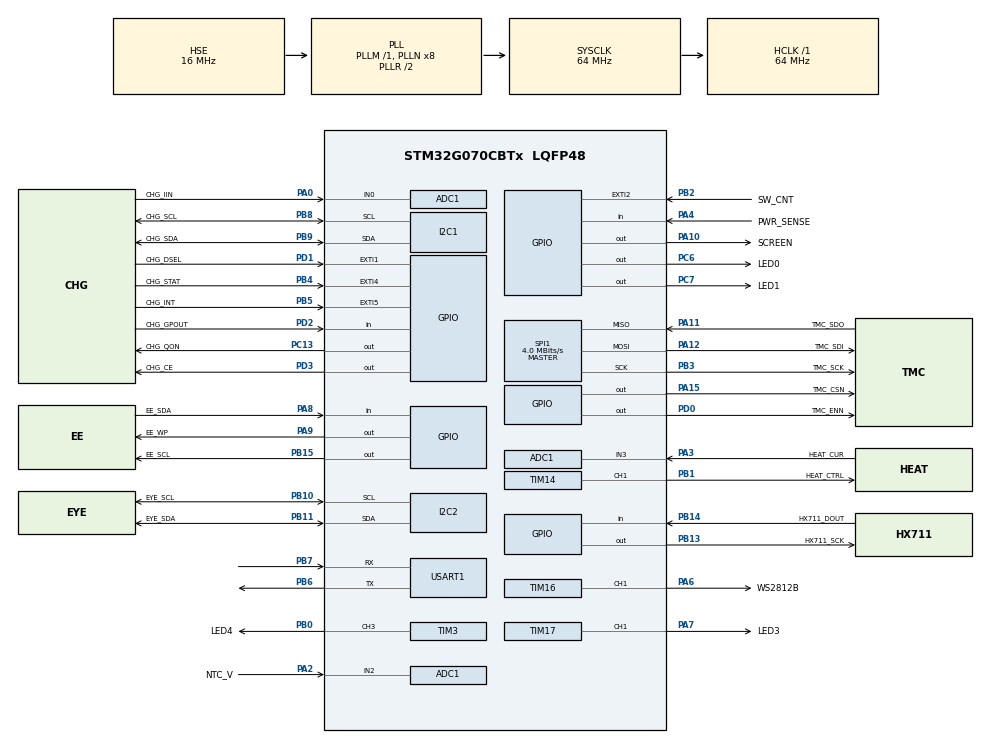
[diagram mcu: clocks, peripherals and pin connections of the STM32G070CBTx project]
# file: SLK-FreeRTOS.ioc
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ADC1.Channel-0\#ChannelRegularConversion=ADC_CHANNEL_0
ADC1.Channel-1\#ChannelRegularConversion=ADC_CHANNEL_2
ADC1.Channel-2\#ChannelRegularConversion=ADC_CHANNEL_3
ADC1.ClockPrescaler=ADC_CLOCK_ASYNC_DIV32
ADC1.ContinuousConvMode=ENABLE
ADC1.DMAContinuousRequests=ENABLE
ADC1.EOCSelection=ADC_EOC_SEQ_CONV
ADC1.NbrOfConversion=3
ADC1.NbrOfConversionFlag=1
ADC1.Overrun=ADC_OVR_DATA_OVERWRITTEN
ADC1.OversamplingMode=ENABLE
ADC1.Rank-0\#ChannelRegularConversion=1
ADC1.Rank-1\#ChannelRegularConversion=2
ADC1.Rank-2\#ChannelRegularConversion=3
ADC1.Ratio=ADC_OVERSAMPLING_RATIO_256
ADC1.Resolution=ADC_RESOLUTION_12B
ADC1.RightBitShift=ADC_RIGHTBITSHIFT_4
ADC1.SamplingTime-0\#ChannelRegularConversion=ADC_SAMPLINGTIME_COMMON_1
ADC1.SamplingTime-1\#ChannelRegularConversion=ADC_SAMPLINGTIME_COMMON_1
ADC1.SamplingTime-2\#ChannelRegularConversion=ADC_SAMPLINGTIME_COMMON_1
ADC1.SelectedChannel=ADC_CHANNEL_0|ADC_CHANNEL_2|ADC_CHANNEL_3
ADC1.master=1
Dma.ADC1.4.Direction=DMA_PERIPH_TO_MEMORY
Dma.ADC1.4.EventEnable=DISABLE
Dma.ADC1.4.Instance=DMA1_Channel5
Dma.ADC1.4.MemDataAlignment=DMA_MDATAALIGN_HALFWORD
Dma.ADC1.4.MemInc=DMA_MINC_ENABLE
Dma.ADC1.4.Mode=DMA_CIRCULAR
Dma.ADC1.4.PeriphDataAlignment=DMA_PDATAALIGN_HALFWORD
Dma.ADC1.4.PeriphInc=DMA_PINC_DISABLE
Dma.ADC1.4.Polarity=HAL_DMAMUX_REQ_GEN_RISING
Dma.ADC1.4.Priority=DMA_PRIORITY_LOW
Dma.ADC1.4.RequestNumber=1
Dma.ADC1.4.SignalID=NONE
Dma.ADC1.4.SyncEnable=DISABLE
Dma.ADC1.4.SyncPolarity=HAL_DMAMUX_SYNC_NO_EVENT
Dma.ADC1.4.SyncRequestNumber=1
Dma.ADC1.4.SyncSignalID=NONE
Dma.I2C1_RX.0.Direction=DMA_PERIPH_TO_MEMORY
Dma.I2C1_RX.0.EventEnable=DISABLE
Dma.I2C1_RX.0.Instance=DMA1_Channel1
Dma.I2C1_RX.0.MemDataAlignment=DMA_MDATAALIGN_BYTE
Dma.I2C1_RX.0.MemInc=DMA_MINC_ENABLE
Dma.I2C1_RX.0.Mode=DMA_NORMAL
Dma.I2C1_RX.0.PeriphDataAlignment=DMA_PDATAALIGN_BYTE
Dma.I2C1_RX.0.PeriphInc=DMA_PINC_DISABLE
Dma.I2C1_RX.0.Polarity=HAL_DMAMUX_REQ_GEN_RISING
Dma.I2C1_RX.0.Priority=DMA_PRIORITY_LOW
Dma.I2C1_RX.0.RequestNumber=1
Dma.I2C1_RX.0.SignalID=NONE
Dma.I2C1_RX.0.SyncEnable=DISABLE
Dma.I2C1_RX.0.SyncPolarity=HAL_DMAMUX_SYNC_NO_EVENT
Dma.I2C1_RX.0.SyncRequestNumber=1
Dma.I2C1_RX.0.SyncSignalID=NONE
Dma.I2C1_TX.1.Direction=DMA_MEMORY_TO_PERIPH
Dma.I2C1_TX.1.EventEnable=DISABLE
Dma.I2C1_TX.1.Instance=DMA1_Channel2
Dma.I2C1_TX.1.MemDataAlignment=DMA_MDATAALIGN_BYTE
Dma.I2C1_TX.1.MemInc=DMA_MINC_ENABLE
Dma.I2C1_TX.1.Mode=DMA_NORMAL
Dma.I2C1_TX.1.PeriphDataAlignment=DMA_PDATAALIGN_BYTE
Dma.I2C1_TX.1.PeriphInc=DMA_PINC_DISABLE
Dma.I2C1_TX.1.Polarity=HAL_DMAMUX_REQ_GEN_RISING
Dma.I2C1_TX.1.Priority=DMA_PRIORITY_LOW
Dma.I2C1_TX.1.RequestNumber=1
Dma.I2C1_TX.1.SignalID=NONE
Dma.I2C1_TX.1.SyncEnable=DISABLE
Dma.I2C1_TX.1.SyncPolarity=HAL_DMAMUX_SYNC_NO_EVENT
Dma.I2C1_TX.1.SyncRequestNumber=1
Dma.I2C1_TX.1.SyncSignalID=NONE
Dma.I2C2_RX.2.Direction=DMA_PERIPH_TO_MEMORY
Dma.I2C2_RX.2.EventEnable=DISABLE
Dma.I2C2_RX.2.Instance=DMA1_Channel3
Dma.I2C2_RX.2.MemDataAlignment=DMA_MDATAALIGN_BYTE
Dma.I2C2_RX.2.MemInc=DMA_MINC_ENABLE
Dma.I2C2_RX.2.Mode=DMA_NORMAL
Dma.I2C2_RX.2.PeriphDataAlignment=DMA_PDATAALIGN_BYTE
Dma.I2C2_RX.2.PeriphInc=DMA_PINC_DISABLE
Dma.I2C2_RX.2.Polarity=HAL_DMAMUX_REQ_GEN_RISING
Dma.I2C2_RX.2.Priority=DMA_PRIORITY_LOW
Dma.I2C2_RX.2.RequestNumber=1
Dma.I2C2_RX.2.SignalID=NONE
Dma.I2C2_RX.2.SyncEnable=DISABLE
Dma.I2C2_RX.2.SyncPolarity=HAL_DMAMUX_SYNC_NO_EVENT
Dma.I2C2_RX.2.SyncRequestNumber=1
Dma.I2C2_RX.2.SyncSignalID=NONE
Dma.I2C2_TX.3.Direction=DMA_MEMORY_TO_PERIPH
Dma.I2C2_TX.3.EventEnable=DISABLE
Dma.I2C2_TX.3.Instance=DMA1_Channel4
Dma.I2C2_TX.3.MemDataAlignment=DMA_MDATAALIGN_BYTE
Dma.I2C2_TX.3.MemInc=DMA_MINC_ENABLE
Dma.I2C2_TX.3.Mode=DMA_NORMAL
Dma.I2C2_TX.3.PeriphDataAlignment=DMA_PDATAALIGN_BYTE
Dma.I2C2_TX.3.PeriphInc=DMA_PINC_DISABLE
Dma.I2C2_TX.3.Polarity=HAL_DMAMUX_REQ_GEN_RISING
Dma.I2C2_TX.3.Priority=DMA_PRIORITY_LOW
Dma.I2C2_TX.3.RequestNumber=1
Dma.I2C2_TX.3.SignalID=NONE
Dma.I2C2_TX.3.SyncEnable=DISABLE
Dma.I2C2_TX.3.SyncPolarity=HAL_DMAMUX_SYNC_NO_EVENT
Dma.I2C2_TX.3.SyncRequestNumber=1
Dma.I2C2_TX.3.SyncSignalID=NONE
Dma.Request0=I2C1_RX
Dma.Request1=I2C1_TX
Dma.Request2=I2C2_RX
Dma.Request3=I2C2_TX
Dma.Request4=ADC1
Dma.Request5=USART1_TX
Dma.Request6=TIM16_CH1
Dma.TIM16_CH1.6.Direction=DMA_MEMORY_TO_PERIPH
Dma.TIM16_CH1.6.EventEnable=DISABLE
Dma.TIM16_CH1.6.Instance=DMA1_Channel7
Dma.TIM16_CH1.6.MemDataAlignment=DMA_MDATAALIGN_HALFWORD
Dma.TIM16_CH1.6.MemInc=DMA_MINC_ENABLE
Dma.TIM16_CH1.6.Mode=DMA_CIRCULAR
Dma.TIM16_CH1.6.PeriphDataAlignment=DMA_PDATAALIGN_HALFWORD
Dma.TIM16_CH1.6.PeriphInc=DMA_PINC_DISABLE
Dma.TIM16_CH1.6.Polarity=HAL_DMAMUX_REQ_GEN_RISING
Dma.TIM16_CH1.6.Priority=DMA_PRIORITY_MEDIUM
Dma.TIM16_CH1.6.RequestNumber=1
Dma.TIM16_CH1.6.SignalID=NONE
Dma.TIM16_CH1.6.SyncEnable=DISABLE
Dma.TIM16_CH1.6.SyncPolarity=HAL_DMAMUX_SYNC_NO_EVENT
Dma.TIM16_CH1.6.SyncRequestNumber=1
Dma.TIM16_CH1.6.SyncSignalID=NONE
Dma.USART1_TX.5.Direction=DMA_MEMORY_TO_PERIPH
Dma.USART1_TX.5.EventEnable=DISABLE
Dma.USART1_TX.5.Instance=DMA1_Channel6
Dma.USART1_TX.5.MemDataAlignment=DMA_MDATAALIGN_BYTE
Dma.USART1_TX.5.MemInc=DMA_MINC_ENABLE
Dma.USART1_TX.5.Mode=DMA_NORMAL
Dma.USART1_TX.5.PeriphDataAlignment=DMA_PDATAALIGN_BYTE
Dma.USART1_TX.5.PeriphInc=DMA_PINC_DISABLE
Dma.USART1_TX.5.Polarity=HAL_DMAMUX_REQ_GEN_RISING
Dma.USART1_TX.5.Priority=DMA_PRIORITY_LOW
Dma.USART1_TX.5.RequestNumber=1
Dma.USART1_TX.5.SignalID=NONE
Dma.USART1_TX.5.SyncEnable=DISABLE
Dma.USART1_TX.5.SyncPolarity=HAL_DMAMUX_SYNC_NO_EVENT
Dma.USART1_TX.5.SyncRequestNumber=1
Dma.USART1_TX.5.SyncSignalID=NONE
FREERTOS.Tasks01=Moto_Task,24,128,AppMoto_Task,Default,NULL,Dynamic,NULL,NULL;myTask02,8,128,StartTask02,Default,NULL,Dynamic,NULL,NULL
I2C1.CustomTiming=Disabled
I2C1.Timing=0x10707DBC
I2C2.Timing=0x10707DBC
Mcu.Family=STM32G0
Mcu.Name=STM32G070CBTx
Mcu.Package=LQFP48
NVIC.ADC1_IRQn=true\:3\:0\:false\:false\:true\:true\:true\:true\:true
NVIC.DMA1_Ch4_7_DMAMUX1_OVR_IRQn=true\:3\:0\:false\:false\:true\:true\:false\:true\:true
NVIC.DMA1_Channel1_IRQn=true\:3\:0\:false\:false\:true\:true\:false\:true\:true
NVIC.DMA1_Channel2_3_IRQn=true\:3\:0\:false\:false\:true\:true\:false\:true\:true
NVIC.EXTI2_3_IRQn=true\:3\:0\:false\:false\:true\:true\:true\:true\:true
NVIC.I2C1_IRQn=true\:3\:0\:false\:false\:true\:true\:true\:true\:true
NVIC.I2C2_IRQn=true\:3\:0\:false\:false\:true\:true\:true\:true\:true
NVIC.TIM6_IRQn=true\:3\:0\:false\:false\:true\:false\:true\:true\:true
NVIC.TimeBase=TIM6_IRQn
NVIC.TimeBaseIP=TIM6
NVIC.USART1_IRQn=true\:3\:0\:false\:false\:true\:true\:true\:true\:true
PA0.GPIO_Label=CHG_IIN
PA0.Mode=IN0
PA0.Signal=ADC1_IN0
PA10.GPIO_FMPA10=__NULL
PA10.GPIO_Label=SCREEN
PA10.GPIO_Speed=GPIO_SPEED_FREQ_LOW
PA10.PinState=GPIO_PIN_SET
PA10.Signal=GPIO_Output
PA11\ [PA9].GPIO_Label=TMC_SDO
PA11\ [PA9].Mode=Full_Duplex_Master
PA11\ [PA9].Signal=SPI1_MISO
PA12\ [PA10].GPIO_Label=TMC_SDI
PA12\ [PA10].Mode=Full_Duplex_Master
PA12\ [PA10].Signal=SPI1_MOSI
PA13.Mode=Serial_Wire
PA13.Signal=SYS_SWDIO
PA14-BOOT0.Mode=Serial_Wire
PA14-BOOT0.Signal=SYS_SWCLK
PA15.GPIO_Label=TMC_CSN
PA15.PinState=GPIO_PIN_SET
PA15.Signal=GPIO_Output
PA2.GPIO_Label=NTC_V
PA2.Mode=IN2
PA2.Signal=ADC1_IN2
PA3.GPIO_Label=HEAT_CUR
PA3.Mode=IN3
PA3.Signal=ADC1_IN3
PA4.GPIO_Label=PWR_SENSE
PA4.GPIO_PuPd=GPIO_PULLDOWN
PA4.Signal=GPIO_Input
PA6.GPIO_Label=WS2812B
PA6.GPIO_Speed=GPIO_SPEED_FREQ_VERY_HIGH
PA6.Signal=S_TIM16_CH1
PA7.GPIO_Label=LED3
PA7.Signal=S_TIM17_CH1
PA8.GPIO_Label=EE_SDA
PA8.Signal=GPIO_Input
PA9.GPIO_Label=EE_WP
PA9.Signal=GPIO_Output
PB0.GPIO_Label=LED4
PB0.Signal=S_TIM3_CH3
PB1.GPIO_Label=HEAT_CTRL
PB1.Signal=S_TIM14_CH1
PB10.GPIO_Label=EYE_SCL
PB10.Mode=I2C
PB10.Signal=I2C2_SCL
PB11.GPIO_Label=EYE_SDA
PB11.Mode=I2C
PB11.Signal=I2C2_SDA
PB13.GPIO_Label=HX711_SCK
PB13.Signal=GPIO_Output
PB14.GPIO_Label=HX711_DOUT
PB14.Signal=GPIO_Input
PB15.GPIO_Label=EE_SCL
PB15.Signal=GPIO_Output
PB2.GPIO_Label=SW_CNT
PB2.GPIO_ModeDefaultEXTI=GPIO_MODE_IT_FALLING
PB2.Signal=GPXTI2
PB3.GPIO_Label=TMC_SCK
PB3.Mode=Full_Duplex_Master
PB3.Signal=SPI1_SCK
PB4.GPIO_Label=CHG_STAT
PB4.Signal=GPXTI4
PB5.GPIO_Label=CHG_INT
PB5.Signal=GPXTI5
PB6.Mode=Asynchronous
PB6.Signal=USART1_TX
PB7.Mode=Asynchronous
PB7.Signal=USART1_RX
PB8.GPIO_Label=CHG_SCL
PB8.Mode=I2C
PB8.Signal=I2C1_SCL
PB9.GPIO_Label=CHG_SDA
PB9.Mode=I2C
PB9.Signal=I2C1_SDA
PC13.GPIO_Label=CHG_QON
PC13.Signal=GPIO_Output
PC14-OSC32_IN\ (PC14).Mode=LSE-External-Oscillator
PC14-OSC32_IN\ (PC14).Signal=RCC_OSC32_IN
PC15-OSC32_OUT\ (PC15).Mode=LSE-External-Oscillator
PC15-OSC32_OUT\ (PC15).Signal=RCC_OSC32_OUT
PC6.GPIO_Label=LED0
PC6.PinState=GPIO_PIN_SET
PC6.Signal=GPIO_Output
PC7.GPIO_Label=LED1
PC7.PinState=GPIO_PIN_SET
PC7.Signal=GPIO_Output
PD0.GPIO_Label=TMC_ENN
PD0.PinState=GPIO_PIN_SET
PD0.Signal=GPIO_Output
PD1.GPIO_Label=CHG_DSEL
PD1.Signal=GPXTI1
PD2.GPIO_Label=CHG_GPOUT
PD2.Signal=GPIO_Input
PD3.GPIO_Label=CHG_CE
PD3.PinState=GPIO_PIN_SET
PD3.Signal=GPIO_Output
PF0-OSC_IN\ (PF0).Mode=HSE-External-Oscillator
PF0-OSC_IN\ (PF0).Signal=RCC_OSC_IN
PF1-OSC_OUT\ (PF1).Mode=HSE-External-Oscillator
PF1-OSC_OUT\ (PF1).Signal=RCC_OSC_OUT
ProjectManager.HeapSize=0x200
ProjectManager.StackSize=0x400
ProjectManager.TargetToolchain=STM32CubeIDE
RCC.ADCFreq_Value=64000000
RCC.AHBFreq_Value=64000000
RCC.CortexFreq_Value=64000000
RCC.EXTERNAL_CLOCK_VALUE=48000
RCC.HCLKFreq_Value=64000000
RCC.HSE_VALUE=16000000
RCC.HSI_VALUE=16000000
RCC.PLLSourceVirtual=RCC_PLLSOURCE_HSE
RCC.SYSCLKFreq_VALUE=64000000
RCC.SYSCLKSource=RCC_SYSCLKSOURCE_PLLCLK
RCC.VCOOutputFreq_Value=128000000
SH.S_TIM14_CH1.0=TIM14_CH1,PWM Generation1 CH1
SH.S_TIM16_CH1.0=TIM16_CH1,PWM Generation1 CH1
SH.S_TIM17_CH1.0=TIM17_CH1,PWM Generation1 CH1
SH.S_TIM3_CH3.0=TIM3_CH3,PWM Generation3 CH3
SPI1.BaudRatePrescaler=SPI_BAUDRATEPRESCALER_16
SPI1.CLKPhase=SPI_PHASE_2EDGE
SPI1.CLKPolarity=SPI_POLARITY_HIGH
SPI1.CalculateBaudRate=4.0 MBits/s
SPI1.DataSize=SPI_DATASIZE_8BIT
SPI1.Direction=SPI_DIRECTION_2LINES
SPI1.Mode=SPI_MODE_MASTER
SPI1.VirtualType=VM_MASTER
TIM14.Channel=TIM_CHANNEL_1
TIM14.Period=255
TIM14.Prescaler=63
TIM16.AutoReloadPreload=TIM_AUTORELOAD_PRELOAD_DISABLE
TIM16.Channel=TIM_CHANNEL_1
TIM16.Period=160
TIM16.Prescaler=0
TIM17.Channel=TIM_CHANNEL_1
TIM17.Period=499
TIM17.Prescaler=63
TIM3.Channel-PWM\ Generation3\ CH3=TIM_CHANNEL_3
TIM3.Period=499
TIM3.Prescaler=63
USART1.VirtualMode-Asynchronous=VM_ASYNC
VP_FREERTOS_VS_CMSIS_V2.Mode=CMSIS_V2
VP_SYS_VS_DBSignals.Mode=DisableDeadBatterySignals
VP_SYS_VS_tim6.Mode=TIM6
VP_TIM14_VS_ClockSourceINT.Mode=Enable_Timer
VP_TIM16_VS_ClockSourceINT.Mode=Enable_Timer
VP_TIM17_VS_ClockSourceINT.Mode=Enable_Timer
board=custom

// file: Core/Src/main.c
/* USER CODE BEGIN Header */
/**
  ******************************************************************************
  * @file           : main.c
  * @brief          : Main program body
  ******************************************************************************
  * @attention
  *
  * Copyright (c) 2024 STMicroelectronics.
  * All rights reserved.
  *
  * This software is licensed under terms that can be found in the LICENSE file
  * in the root directory of this software component.
  * If no LICENSE file comes with this software, it is provided AS-IS.
  *
  ******************************************************************************
  */
/* USER CODE END Header */
#include "main.h"
#include "cmsis_os.h"
#include "adc.h"
#include "dma.h"
#include "i2c.h"
#include "spi.h"
#include "tim.h"
#include "usart.h"
#include "gpio.h"

void SystemClock_Config(void);
void MX_FREERTOS_Init(void);

int main(void)
{

  /* MCU Configuration--------------------------------------------------------*/

  /* Reset of all peripherals, Initializes the Flash interface and the Systick. */
  HAL_Init();

  /* Configure the system clock */
  SystemClock_Config();

  /* Initialize all configured peripherals */
  MX_GPIO_Init();
  MX_DMA_Init();
  MX_ADC1_Init();
  MX_I2C1_Init();
  MX_I2C2_Init();
  MX_SPI1_Init();
  MX_USART1_UART_Init();
  MX_TIM3_Init();
  MX_TIM14_Init();
  MX_TIM16_Init();
  MX_TIM17_Init();

  /* Init scheduler */
  osKernelInitialize();  /* Call init function for freertos objects (in freertos.c) */
  MX_FREERTOS_Init();

  /* Start scheduler */
  osKernelStart();

  /* We should never get here as control is now taken by the scheduler */
  /* Infinite loop */
  while (1)
  {

  }
}

void SystemClock_Config(void)
{
  RCC_OscInitTypeDef RCC_OscInitStruct = {0};
  RCC_ClkInitTypeDef RCC_ClkInitStruct = {0};

  /** Configure the main internal regulator output voltage
  */
  HAL_PWREx_ControlVoltageScaling(PWR_REGULATOR_VOLTAGE_SCALE1);

  /** Initializes the RCC Oscillators according to the specified parameters
  * in the RCC_OscInitTypeDef structure.
  */
  RCC_OscInitStruct.OscillatorType = RCC_OSCILLATORTYPE_HSE;
  RCC_OscInitStruct.HSEState = RCC_HSE_ON;
  RCC_OscInitStruct.PLL.PLLState = RCC_PLL_ON;
  RCC_OscInitStruct.PLL.PLLSource = RCC_PLLSOURCE_HSE;
  RCC_OscInitStruct.PLL.PLLM = RCC_PLLM_DIV1;
  RCC_OscInitStruct.PLL.PLLN = 8;
  RCC_OscInitStruct.PLL.PLLP = RCC_PLLP_DIV2;
  RCC_OscInitStruct.PLL.PLLR = RCC_PLLR_DIV2;
  if (HAL_RCC_OscConfig(&RCC_OscInitStruct) != HAL_OK)
  {
    Error_Handler();
  }

  /** Initializes the CPU, AHB and APB buses clocks
  */
  RCC_ClkInitStruct.ClockType = RCC_CLOCKTYPE_HCLK|RCC_CLOCKTYPE_SYSCLK
                              |RCC_CLOCKTYPE_PCLK1;
  RCC_ClkInitStruct.SYSCLKSource = RCC_SYSCLKSOURCE_PLLCLK;
  RCC_ClkInitStruct.AHBCLKDivider = RCC_SYSCLK_DIV1;
  RCC_ClkInitStruct.APB1CLKDivider = RCC_HCLK_DIV1;

  if (HAL_RCC_ClockConfig(&RCC_ClkInitStruct, FLASH_LATENCY_2) != HAL_OK)
  {
    Error_Handler();
  }
}

void HAL_TIM_PeriodElapsedCallback(TIM_HandleTypeDef *htim)
{
  if (htim->Instance == TIM6) {
    HAL_IncTick();
  }
}

void Error_Handler(void)
{
  __disable_irq();
  while (1)
  {
  }
}

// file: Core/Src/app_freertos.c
/* USER CODE BEGIN Header */
/**
  ******************************************************************************
  * File Name          : app_freertos.c
  * Description        : Code for freertos applications
  ******************************************************************************
  * @attention
  *
  * Copyright (c) 2024 STMicroelectronics.
  * All rights reserved.
  *
  * This software is licensed under terms that can be found in the LICENSE file
  * in the root directory of this software component.
  * If no LICENSE file comes with this software, it is provided AS-IS.
  *
  ******************************************************************************
  */
/* USER CODE END Header */

#include "FreeRTOS.h"
#include "task.h"
#include "main.h"
#include "cmsis_os.h"

/* Definitions for Moto_Task */
osThreadId_t Moto_TaskHandle;
const osThreadAttr_t Moto_Task_attributes = {
  .name = "Moto_Task",
  .priority = (osPriority_t) osPriorityNormal,
  .stack_size = 128 * 4
};
/* Definitions for myTask02 */
osThreadId_t myTask02Handle;
const osThreadAttr_t myTask02_attributes = {
  .name = "myTask02",
  .priority = (osPriority_t) osPriorityLow,
  .stack_size = 128 * 4
};

void AppMoto_Task(void *argument);
void StartTask02(void *argument);

void MX_FREERTOS_Init(void); /* (MISRA C 2004 rule 8.1) */

void MX_FREERTOS_Init(void) {

  /* Create the thread(s) */
  /* creation of Moto_Task */
  Moto_TaskHandle = osThreadNew(AppMoto_Task, NULL, &Moto_Task_attributes);

  /* creation of myTask02 */
  myTask02Handle = osThreadNew(StartTask02, NULL, &myTask02_attributes);

}

void AppMoto_Task(void *argument)
{
  /* USER CODE BEGIN AppMoto_Task */
    TMC5130_Init();
    HAL_GPIO_WritePin(TMC_ENN_GPIO_Port,TMC_ENN_Pin,GPIO_PIN_RESET);
    TMC5130_Write(0xa7, 0x20000);
    //MotorChecking();

    /* Infinite loop */
    for (;;) {

        HAL_GPIO_TogglePin(GPIOC, GPIO_PIN_6);

        TMC5130_Write(0xa0, 2);
        vTaskDelay(1000);
        TMC5130_Write(0xa0, 1);
        vTaskDelay(1000);

    }
  /* USER CODE END AppMoto_Task */
}

void StartTask02(void *argument)
{
  /* USER CODE BEGIN StartTask02 */
  /* Infinite loop */
  for(;;)
  {
      vTaskDelay(500);
      HAL_GPIO_TogglePin(GPIOC, GPIO_PIN_7);
  }
  /* USER CODE END StartTask02 */
}
